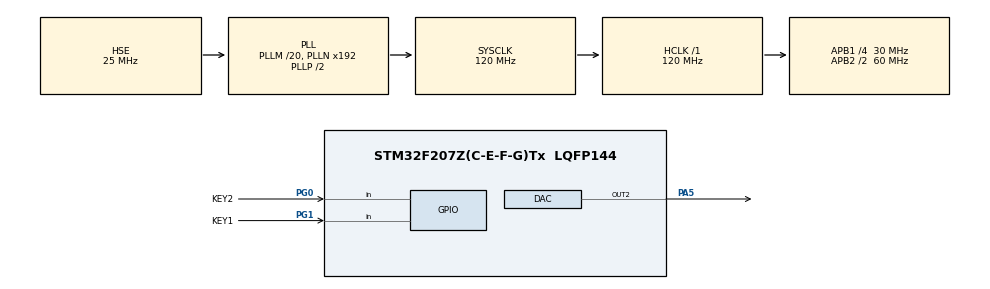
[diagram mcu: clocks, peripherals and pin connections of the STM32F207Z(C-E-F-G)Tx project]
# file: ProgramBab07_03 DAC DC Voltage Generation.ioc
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Mcu.Family=STM32F2
Mcu.Name=STM32F207Z(C-E-F-G)Tx
Mcu.Package=LQFP144
NVIC.PriorityGroup=NVIC_PRIORITYGROUP_4
PA5.Signal=COMP_DAC2_group
PG0.GPIO_Label=KEY2
PG0.Signal=GPIO_Input
PG1.GPIO_Label=KEY1
PG1.Signal=GPIO_Input
PH0-OSC_IN.Mode=HSE-External-Oscillator
PH0-OSC_IN.Signal=RCC_OSC_IN
PH1-OSC_OUT.Mode=HSE-External-Oscillator
PH1-OSC_OUT.Signal=RCC_OSC_OUT
ProjectManager.HeapSize=0x200
ProjectManager.StackSize=0x400
ProjectManager.TargetToolchain=STM32CubeIDE
RCC.48MHZClocksFreq_Value=60000000
RCC.AHBFreq_Value=120000000
RCC.APB1CLKDivider=RCC_HCLK_DIV4
RCC.APB1Freq_Value=30000000
RCC.APB1TimFreq_Value=60000000
RCC.APB2CLKDivider=RCC_HCLK_DIV2
RCC.APB2Freq_Value=60000000
RCC.APB2TimFreq_Value=120000000
RCC.CortexFreq_Value=120000000
RCC.HCLKFreq_Value=120000000
RCC.HSE_VALUE=25000000
RCC.HSI_VALUE=16000000
RCC.LSE_VALUE=32768
RCC.PLLM=20
RCC.PLLSourceVirtual=RCC_PLLSOURCE_HSE
RCC.SYSCLKFreq_VALUE=120000000
RCC.SYSCLKSource=RCC_SYSCLKSOURCE_PLLCLK
RCC.VCOOutputFreq_Value=240000000
SH.COMP_DAC2_group.0=DAC_OUT2,DAC_OUT2
board=custom

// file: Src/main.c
/* USER CODE BEGIN Header */
/**
  ******************************************************************************
  * @file           : main.c
  * @brief          : Main program body
  ******************************************************************************
  * @attention
  *
  * <h2><center>&copy; Copyright (c) 2019 STMicroelectronics.
  * All rights reserved.</center></h2>
  *
  * This software component is licensed by ST under BSD 3-Clause license,
  * the "License"; You may not use this file except in compliance with the
  * License. You may obtain a copy of the License at:
  *                        opensource.org/licenses/BSD-3-Clause
  *
  ******************************************************************************
  */
/* USER CODE END Header */

#include "main.h"
#include "dac.h"
#include "gpio.h"

/* USER CODE BEGIN PV */
uint8_t DAC_Value=0;
uint16_t keypresstimer;
uint8_t KeyPressed;
/* USER CODE END PV */

void SystemClock_Config(void);

int main(void)
{

  /* MCU Configuration--------------------------------------------------------*/

  /* Reset of all peripherals, Initializes the Flash interface and the Systick. */
  HAL_Init();

  /* Configure the system clock */
  SystemClock_Config();

  /* Initialize all configured peripherals */
  MX_GPIO_Init();
  MX_DAC_Init();
  /* USER CODE BEGIN 2 */
  DAC_Value = 127;
  if(HAL_DAC_SetValue(&hdac, DAC_CHANNEL_2, DAC_ALIGN_8B_R, DAC_Value) != HAL_OK)
  {
    /* Setting value Error */
    Error_Handler();
  }

  /*##-4- Enable DAC Channel1 ################################################*/
  if(HAL_DAC_Start(&hdac, DAC_CHANNEL_2) != HAL_OK)
  {
    /* Start Error */
    Error_Handler();
  }

  /* USER CODE END 2 */

  /* Infinite loop */
  while (1)
  {

    /* USER CODE BEGIN 3 */
	  //Read Up Key
	  if(!HAL_GPIO_ReadPin(KEY1_GPIO_Port, KEY1_Pin)){
		  keypresstimer=0;
		  while(!HAL_GPIO_ReadPin(KEY1_GPIO_Port, KEY1_Pin)){
			  keypresstimer++;
			  HAL_Delay(1);
		  }
		  if(keypresstimer>10){
		    KeyPressed=1;
		      DAC_Value+=20;
		  }
	  }

	  if(!HAL_GPIO_ReadPin(KEY2_GPIO_Port, KEY2_Pin)){
		  keypresstimer=0;
		  while(!HAL_GPIO_ReadPin(KEY2_GPIO_Port, KEY2_Pin)){
			  keypresstimer++;
			  HAL_Delay(1);
		  }
		  if(keypresstimer>10){
		    KeyPressed=1;
		      DAC_Value-=20;
		  }
	  }

	  if(KeyPressed){
		  if(HAL_DAC_SetValue(&hdac, DAC_CHANNEL_2, DAC_ALIGN_8B_R, DAC_Value) != HAL_OK)
		  {
		    /* Setting value Error */
		    Error_Handler();
		  }

		HAL_DAC_Start(&hdac, DAC_CHANNEL_2);// != HAL_OK)
//		  {
//		    /* Start Error */
//		    Error_Handler();
//		  }

		  KeyPressed=0;

	  }

  }
  /* USER CODE END 3 */
}

void SystemClock_Config(void)
{
  RCC_OscInitTypeDef RCC_OscInitStruct = {0};
  RCC_ClkInitTypeDef RCC_ClkInitStruct = {0};

  /** Initializes the CPU, AHB and APB busses clocks
  */
  RCC_OscInitStruct.OscillatorType = RCC_OSCILLATORTYPE_HSE;
  RCC_OscInitStruct.HSEState = RCC_HSE_ON;
  RCC_OscInitStruct.PLL.PLLState = RCC_PLL_ON;
  RCC_OscInitStruct.PLL.PLLSource = RCC_PLLSOURCE_HSE;
  RCC_OscInitStruct.PLL.PLLM = 20;
  RCC_OscInitStruct.PLL.PLLN = 192;
  RCC_OscInitStruct.PLL.PLLP = RCC_PLLP_DIV2;
  RCC_OscInitStruct.PLL.PLLQ = 4;
  if (HAL_RCC_OscConfig(&RCC_OscInitStruct) != HAL_OK)
  {
    Error_Handler();
  }
  /** Initializes the CPU, AHB and APB busses clocks
  */
  RCC_ClkInitStruct.ClockType = RCC_CLOCKTYPE_HCLK|RCC_CLOCKTYPE_SYSCLK
                              |RCC_CLOCKTYPE_PCLK1|RCC_CLOCKTYPE_PCLK2;
  RCC_ClkInitStruct.SYSCLKSource = RCC_SYSCLKSOURCE_PLLCLK;
  RCC_ClkInitStruct.AHBCLKDivider = RCC_SYSCLK_DIV1;
  RCC_ClkInitStruct.APB1CLKDivider = RCC_HCLK_DIV4;
  RCC_ClkInitStruct.APB2CLKDivider = RCC_HCLK_DIV2;

  if (HAL_RCC_ClockConfig(&RCC_ClkInitStruct, FLASH_LATENCY_3) != HAL_OK)
  {
    Error_Handler();
  }
}

void Error_Handler(void)
{
}

/************************ (C) COPYRIGHT STMicroelectronics *****END OF FILE****/
